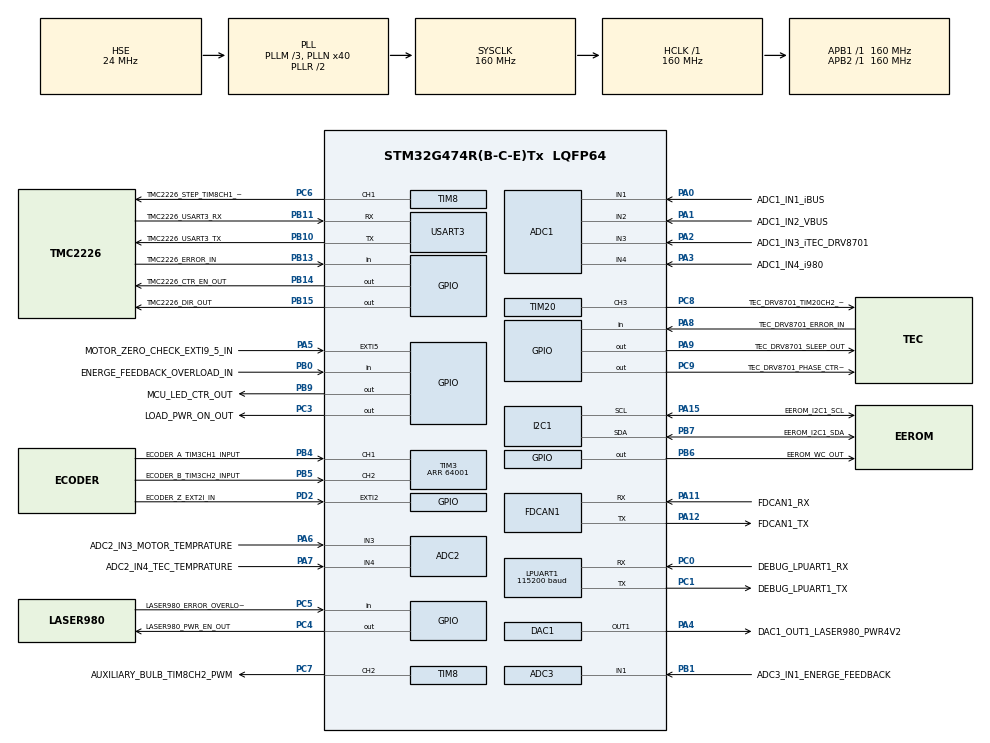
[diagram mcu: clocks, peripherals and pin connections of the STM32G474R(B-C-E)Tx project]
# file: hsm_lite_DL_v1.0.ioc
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ADC1.Channel-10\#ChannelRegularConversion=ADC_CHANNEL_3
ADC1.Channel-11\#ChannelRegularConversion=ADC_CHANNEL_4
ADC1.Channel-8\#ChannelRegularConversion=ADC_CHANNEL_1
ADC1.Channel-9\#ChannelRegularConversion=ADC_CHANNEL_2
ADC1.ContinuousConvMode=DISABLE
ADC1.DMAContinuousRequests=ENABLE
ADC1.DiscontinuousConvMode=DISABLE
ADC1.EOCSelection=ADC_EOC_SEQ_CONV
ADC1.EnableInjectedConversion=DISABLE
ADC1.EnableInjectedOversampling=DISABLE
ADC1.EnableRegularConversion=ENABLE
ADC1.ExternalTrigConv=ADC_EXTERNALTRIG_T1_TRGO2
ADC1.ExternalTrigConvEdge=ADC_EXTERNALTRIGCONVEDGE_FALLING
ADC1.LowPowerAutoWait=ENABLE
ADC1.Mode=ADC_MODE_INDEPENDENT
ADC1.NbrOfConversion=4
ADC1.NbrOfConversionFlag=1
ADC1.OffsetNumber-10\#ChannelRegularConversion=ADC_OFFSET_NONE
ADC1.OffsetNumber-11\#ChannelRegularConversion=ADC_OFFSET_NONE
ADC1.OffsetNumber-8\#ChannelRegularConversion=ADC_OFFSET_NONE
ADC1.OffsetNumber-9\#ChannelRegularConversion=ADC_OFFSET_NONE
ADC1.Rank-10\#ChannelRegularConversion=3
ADC1.Rank-11\#ChannelRegularConversion=4
ADC1.Rank-8\#ChannelRegularConversion=1
ADC1.Rank-9\#ChannelRegularConversion=2
ADC1.SamplingTime-10\#ChannelRegularConversion=ADC_SAMPLETIME_640CYCLES_5
ADC1.SamplingTime-11\#ChannelRegularConversion=ADC_SAMPLETIME_640CYCLES_5
ADC1.SamplingTime-8\#ChannelRegularConversion=ADC_SAMPLETIME_640CYCLES_5
ADC1.SamplingTime-9\#ChannelRegularConversion=ADC_SAMPLETIME_640CYCLES_5
ADC1.master=1
ADC2.Channel-0\#ChannelRegularConversion=ADC_CHANNEL_3
ADC2.Channel-1\#ChannelRegularConversion=ADC_CHANNEL_4
ADC2.ContinuousConvMode=DISABLE
ADC2.DMAContinuousRequests=ENABLE
ADC2.EOCSelection=ADC_EOC_SEQ_CONV
ADC2.ExternalTrigConv=ADC_EXTERNALTRIG_T1_TRGO
ADC2.ExternalTrigConvEdge=ADC_EXTERNALTRIGCONVEDGE_RISING
ADC2.LowPowerAutoWait=ENABLE
ADC2.NbrOfConversion=2
ADC2.NbrOfConversionFlag=1
ADC2.OffsetNumber-0\#ChannelRegularConversion=ADC_OFFSET_NONE
ADC2.OffsetNumber-1\#ChannelRegularConversion=ADC_OFFSET_NONE
ADC2.Rank-0\#ChannelRegularConversion=1
ADC2.Rank-1\#ChannelRegularConversion=2
ADC2.SamplingTime-0\#ChannelRegularConversion=ADC_SAMPLETIME_640CYCLES_5
ADC2.SamplingTime-1\#ChannelRegularConversion=ADC_SAMPLETIME_640CYCLES_5
ADC3.Channel-0\#ChannelRegularConversion=ADC_CHANNEL_1
ADC3.DMAContinuousRequests=ENABLE
ADC3.ExternalTrigConv=ADC_EXTERNALTRIG_T15_TRGO
ADC3.LowPowerAutoWait=ENABLE
ADC3.NbrOfConversionFlag=1
ADC3.OffsetNumber-0\#ChannelRegularConversion=ADC_OFFSET_NONE
ADC3.Rank-0\#ChannelRegularConversion=1
ADC3.SamplingTime-0\#ChannelRegularConversion=ADC_SAMPLETIME_247CYCLES_5
ADC3.master=1
DAC1.DAC_Trigger_OUT1-DAC_OUT1=DAC_TRIGGER_SOFTWARE
Dma.ADC1.0.Direction=DMA_PERIPH_TO_MEMORY
Dma.ADC1.0.EventEnable=DISABLE
Dma.ADC1.0.Instance=DMA1_Channel1
Dma.ADC1.0.MemDataAlignment=DMA_MDATAALIGN_HALFWORD
Dma.ADC1.0.MemInc=DMA_MINC_ENABLE
Dma.ADC1.0.Mode=DMA_CIRCULAR
Dma.ADC1.0.PeriphDataAlignment=DMA_PDATAALIGN_HALFWORD
Dma.ADC1.0.PeriphInc=DMA_PINC_DISABLE
Dma.ADC1.0.Polarity=HAL_DMAMUX_REQ_GEN_RISING
Dma.ADC1.0.Priority=DMA_PRIORITY_LOW
Dma.ADC1.0.RequestNumber=1
Dma.ADC1.0.SignalID=NONE
Dma.ADC1.0.SyncEnable=DISABLE
Dma.ADC1.0.SyncPolarity=HAL_DMAMUX_SYNC_NO_EVENT
Dma.ADC1.0.SyncRequestNumber=1
Dma.ADC1.0.SyncSignalID=NONE
Dma.ADC2.2.Direction=DMA_PERIPH_TO_MEMORY
Dma.ADC2.2.EventEnable=DISABLE
Dma.ADC2.2.Instance=DMA1_Channel2
Dma.ADC2.2.MemDataAlignment=DMA_MDATAALIGN_HALFWORD
Dma.ADC2.2.MemInc=DMA_MINC_ENABLE
Dma.ADC2.2.Mode=DMA_CIRCULAR
Dma.ADC2.2.PeriphDataAlignment=DMA_PDATAALIGN_HALFWORD
Dma.ADC2.2.PeriphInc=DMA_PINC_DISABLE
Dma.ADC2.2.Polarity=HAL_DMAMUX_REQ_GEN_RISING
Dma.ADC2.2.Priority=DMA_PRIORITY_LOW
Dma.ADC2.2.RequestNumber=1
Dma.ADC2.2.SignalID=NONE
Dma.ADC2.2.SyncEnable=DISABLE
Dma.ADC2.2.SyncPolarity=HAL_DMAMUX_SYNC_NO_EVENT
Dma.ADC2.2.SyncRequestNumber=1
Dma.ADC2.2.SyncSignalID=NONE
Dma.ADC3.1.Direction=DMA_PERIPH_TO_MEMORY
Dma.ADC3.1.EventEnable=DISABLE
Dma.ADC3.1.Instance=DMA2_Channel1
Dma.ADC3.1.MemDataAlignment=DMA_MDATAALIGN_HALFWORD
Dma.ADC3.1.MemInc=DMA_MINC_ENABLE
Dma.ADC3.1.Mode=DMA_CIRCULAR
Dma.ADC3.1.PeriphDataAlignment=DMA_PDATAALIGN_HALFWORD
Dma.ADC3.1.PeriphInc=DMA_PINC_DISABLE
Dma.ADC3.1.Polarity=HAL_DMAMUX_REQ_GEN_RISING
Dma.ADC3.1.Priority=DMA_PRIORITY_LOW
Dma.ADC3.1.RequestNumber=1
Dma.ADC3.1.SignalID=NONE
Dma.ADC3.1.SyncEnable=DISABLE
Dma.ADC3.1.SyncPolarity=HAL_DMAMUX_SYNC_NO_EVENT
Dma.ADC3.1.SyncRequestNumber=1
Dma.ADC3.1.SyncSignalID=NONE
Dma.Request0=ADC1
Dma.Request1=ADC3
Dma.Request2=ADC2
FDCAN1.AutoRetransmission=DISABLE
FDCAN1.CalculateBaudRateNominal=125000
FDCAN1.CalculateTimeBitNominal=8000
FDCAN1.CalculateTimeQuantumNominal=400.0
FDCAN1.ClockDivider=FDCAN_CLOCK_DIV1
FDCAN1.DataSyncJumpWidth=1
FDCAN1.DataTimeSeg1=8
FDCAN1.DataTimeSeg2=9
FDCAN1.Mode=FDCAN_MODE_NORMAL
FDCAN1.NominalPrescaler=64
FDCAN1.NominalSyncJumpWidth=1
FDCAN1.NominalTimeSeg1=10
FDCAN1.NominalTimeSeg2=9
FDCAN1.StdFiltersNbr=0
FDCAN1.TransmitPause=DISABLE
FREERTOS.BinarySemaphores01=prohotBinarySem02,Dynamic,NULL,Depleted;laserCloseBinarySem03,Dynamic,NULL,Depleted;poweroffBinarySem04,Dynamic,NULL,Depleted;secondHeartBinarySem04,Dynamic,NULL,Depleted
FREERTOS.Events01=motorEvent01,Dynamic,NULL;laserEvent02,Dynamic,NULL;deviceErrorEvent03,Dynamic,NULL;tecEvent04,Dynamic,NULL
FREERTOS.Queues01=motorPositonQueue01,4,uint32_t,0,Static,positonQueue01Buffer,positonQueue01ControlBlock
FREERTOS.Tasks01=defaultTask,26,256,StartDefaultTask,Default,NULL,Dynamic,NULL,NULL;myTask02,24,256,motorTask02,Default,NULL,Dynamic,NULL,NULL;myTask03,26,320,CANopenTask03,Default,NULL,Dynamic,NULL,NULL;myTask04,26,256,laserWorkTask04,Default,NULL,Dynamic,NULL,NULL;myTask05,27,256,laserProhotTask05,Default,NULL,Dynamic,NULL,NULL;myTask06,28,128,powerOffTask06,Default,NULL,Dynamic,NULL,NULL
FREERTOS.Timers01=laserWorkTimer01,laserWorkTimerCallback01,osTimerOnce,Default,NULL,Static,laserWorkTimer01ControlBlock;tecRunTimer02,tecRunCallback02,osTimerOnce,Default,NULL,Dynamic,NULL;secondsHeartTimer03,secondsHeartCallback03,osTimerPeriodic,Default,NULL,Dynamic,NULL
FREERTOS.configENABLE_FPU=1
FREERTOS.configTOTAL_HEAP_SIZE=32768
FREERTOS.configUSE_IDLE_HOOK=1
I2C1.Timing=0x30D29DE4
LPUART1.BaudRate=115200
LPUART1.FIFOMode=UART_FIFOMODE_DISABLE
LPUART1.Mode=UART_MODE_TX_RX
Mcu.Family=STM32G4
Mcu.Name=STM32G474R(B-C-E)Tx
Mcu.Package=LQFP64
NVIC.DMA1_Channel1_IRQn=true\:5\:0\:false\:false\:true\:true\:false\:true\:true
NVIC.DMA1_Channel2_IRQn=true\:5\:0\:false\:false\:true\:true\:false\:true\:true
NVIC.DMA2_Channel1_IRQn=true\:5\:0\:false\:false\:true\:false\:false\:true\:true
NVIC.EXTI2_IRQn=true\:5\:0\:false\:false\:true\:true\:true\:true\:true
NVIC.PriorityGroup=NVIC_PRIORITYGROUP_4
NVIC.TIM3_IRQn=true\:5\:0\:false\:false\:true\:true\:true\:true\:true
NVIC.TIM4_IRQn=true\:5\:0\:false\:false\:true\:true\:true\:true\:true
NVIC.TIM6_DAC_IRQn=true\:15\:0\:false\:false\:true\:false\:false\:true\:true
NVIC.TimeBase=TIM6_DAC_IRQn
NVIC.TimeBaseIP=TIM6
PA0.GPIO_Label=ADC1_IN1_iBUS
PA0.Mode=IN1-Single-Ended
PA0.Signal=ADC1_IN1
PA1.GPIO_Label=ADC1_IN2_VBUS
PA1.Mode=IN2-Single-Ended
PA1.Signal=ADC1_IN2
PA11.GPIO_Label=FDCAN1_RX
PA11.GPIO_PuPd=GPIO_NOPULL
PA11.Mode=FDCAN_Activate
PA11.Signal=FDCAN1_RX
PA12.GPIO_Label=FDCAN1_TX
PA12.GPIO_PuPd=GPIO_NOPULL
PA12.GPIO_Speed=GPIO_SPEED_FREQ_MEDIUM
PA12.Mode=FDCAN_Activate
PA12.Signal=FDCAN1_TX
PA13.Mode=Serial_Wire
PA13.Signal=SYS_JTMS-SWDIO
PA14.Mode=Serial_Wire
PA14.Signal=SYS_JTCK-SWCLK
PA15.GPIO_Label=EEROM_I2C1_SCL
PA15.Mode=I2C
PA15.Signal=I2C1_SCL
PA2.GPIO_Label=ADC1_IN3_iTEC_DRV8701
PA2.Mode=IN3-Single-Ended
PA2.Signal=ADC1_IN3
PA3.GPIO_Label=ADC1_IN4_i980
PA3.Mode=IN4-Single-Ended
PA3.Signal=ADC1_IN4
PA4.GPIO_Label=DAC1_OUT1_LASER980_PWR4V2
PA4.Signal=COMP_DAC11_group
PA5.GPIO_Label=MOTOR_ZERO_CHECK_EXTI9_5_IN
PA5.GPIO_ModeDefaultEXTI=GPIO_MODE_IT_RISING
PA5.Signal=GPXTI5
PA6.GPIO_Label=ADC2_IN3_MOTOR_TEMPRATURE
PA6.Mode=IN3-Single-Ended
PA6.Signal=ADC2_IN3
PA7.GPIO_Label=ADC2_IN4_TEC_TEMPRATURE
PA7.Mode=IN4-Single-Ended
PA7.Signal=ADC2_IN4
PA8.GPIO_Label=TEC_DRV8701_ERROR_IN
PA8.Signal=GPIO_Input
PA9.GPIO_Label=TEC_DRV8701_SLEEP_OUT
PA9.GPIO_ModeDefaultOutputPP=GPIO_MODE_OUTPUT_PP
PA9.GPIO_PuPd=GPIO_NOPULL
PA9.Signal=GPIO_Output
PB0.GPIO_Label=ENERGE_FEEDBACK_OVERLOAD_IN
PB0.Signal=GPIO_Input
PB1.GPIO_Label=ADC3_IN1_ENERGE_FEEDBACK
PB1.Mode=IN1-Single-Ended
PB1.Signal=ADC3_IN1
PB10.GPIO_Label=TMC2226_USART3_TX
PB10.Mode=Asynchronous
PB10.Signal=USART3_TX
PB11.GPIO_Label=TMC2226_USART3_RX
PB11.Mode=Asynchronous
PB11.Signal=USART3_RX
PB13.GPIO_Label=TMC2226_ERROR_IN
PB13.Signal=GPIO_Input
PB14.GPIO_Label=TMC2226_CTR_EN_OUT
PB14.Signal=GPIO_Output
PB15.GPIO_Label=TMC2226_DIR_OUT
PB15.Signal=GPIO_Output
PB4.GPIO_Label=ECODER_A_TIM3CH1_INPUT
PB4.Signal=S_TIM3_CH1
PB5.GPIO_Label=ECODER_B_TIM3CH2_INPUT
PB5.Signal=S_TIM3_CH2
PB6.GPIO_Label=EEROM_WC_OUT
PB6.Signal=GPIO_Output
PB7.GPIO_Label=EEROM_I2C1_SDA
PB7.Mode=I2C
PB7.Signal=I2C1_SDA
PB9.GPIO_Label=MCU_LED_CTR_OUT
PB9.Signal=GPIO_Output
PC0.GPIO_Label=DEBUG_LPUART1_RX
PC0.Mode=Asynchronous
PC0.Signal=LPUART1_RX
PC1.GPIO_Label=DEBUG_LPUART1_TX
PC1.Mode=Asynchronous
PC1.Signal=LPUART1_TX
PC3.GPIO_Label=LOAD_PWR_ON_OUT
PC3.Signal=GPIO_Output
PC4.GPIO_Label=LASER980_PWR_EN_OUT
PC4.Signal=GPIO_Output
PC5.GPIO_Label=LASER980_ERROR_OVERLOAD_IN
PC5.Signal=GPIO_Input
PC6.GPIO_Label=TMC2226_STEP_TIM8CH1_PWM
PC6.Signal=S_TIM8_CH1
PC7.GPIO_Label=AUXILIARY_BULB_TIM8CH2_PWM
PC7.Signal=S_TIM8_CH2
PC8.GPIO_Label=TEC_DRV8701_TIM20CH2_PWM
PC8.Signal=S_TIM20_CH3
PC9.GPIO_Label=TEC_DRV8701_PHASE_CTR_OUT
PC9.Signal=GPIO_Output
PD2.GPIO_Label=ECODER_Z_EXT2I_IN
PD2.GPIO_ModeDefaultEXTI=GPIO_MODE_IT_FALLING
PD2.Signal=GPXTI2
PF0-OSC_IN.Mode=HSE-External-Oscillator
PF0-OSC_IN.Signal=RCC_OSC_IN
PF1-OSC_OUT.Mode=HSE-External-Oscillator
PF1-OSC_OUT.Signal=RCC_OSC_OUT
ProjectManager.HeapSize=0x2000
ProjectManager.StackSize=0x400
ProjectManager.TargetToolchain=MDK-ARM V5.32
RCC.ADC12Freq_Value=160000000
RCC.ADC345Freq_Value=160000000
RCC.AHBFreq_Value=160000000
RCC.APB1Freq_Value=160000000
RCC.APB1TimFreq_Value=160000000
RCC.APB2Freq_Value=160000000
RCC.APB2TimFreq_Value=160000000
RCC.CortexFreq_Value=160000000
RCC.EXTERNAL_CLOCK_VALUE=12288000
RCC.HCLKFreq_Value=160000000
RCC.HSE_VALUE=24000000
RCC.HSI48_VALUE=48000000
RCC.HSI_VALUE=16000000
RCC.LSE_VALUE=32768
RCC.PLLM=RCC_PLLM_DIV3
RCC.PLLN=40
RCC.PLLSourceVirtual=RCC_PLLSOURCE_HSE
RCC.SYSCLKFreq_VALUE=160000000
RCC.SYSCLKSource=RCC_SYSCLKSOURCE_PLLCLK
RCC.USBFreq_Value=160000000
RCC.VCOOutputFreq_Value=320000000
SH.COMP_DAC11_group.0=DAC1_OUT1,DAC_OUT1
SH.S_TIM20_CH3.0=TIM20_CH3,PWM Generation3 CH3
SH.S_TIM3_CH1.0=TIM3_CH1,Encoder_Interface
SH.S_TIM3_CH2.0=TIM3_CH2,Encoder_Interface
SH.S_TIM8_CH1.0=TIM8_CH1,PWM Generation1 CH1
SH.S_TIM8_CH2.0=TIM8_CH2,PWM Generation2 CH2
TIM1.AutoReloadPreload=TIM_AUTORELOAD_PRELOAD_ENABLE
TIM1.Channel-Output\ Compare1\ No\ Output=TIM_CHANNEL_1
TIM1.PeriodNoDither=3999
TIM1.Prescaler=1599
TIM1.PulseNoDither_1=1999
TIM1.TIM_MasterOutputTrigger=TIM_TRGO_UPDATE
TIM1.TIM_MasterOutputTrigger2=TIM_TRGO2_OC1
TIM1.TIM_MasterSlaveMode=TIM_MASTERSLAVEMODE_ENABLE
TIM15.AutoReloadPreload=TIM_AUTORELOAD_PRELOAD_ENABLE
TIM15.PeriodNoDither=1999
TIM15.Prescaler=1599
TIM15.TIM_MasterOutputTrigger=TIM_TRGO_UPDATE
TIM15.TIM_MasterSlaveMode=TIM_MASTERSLAVEMODE_ENABLE
TIM20.AutoReloadPreload=TIM_AUTORELOAD_PRELOAD_ENABLE
TIM20.Channel-PWM\ Generation3\ CH3=TIM_CHANNEL_3
TIM20.PeriodNoDither=100
TIM20.Prescaler=15
TIM20.TIM_MasterOutputTrigger=TIM_TRGO_RESET
TIM20.TIM_MasterSlaveMode=TIM_MASTERSLAVEMODE_ENABLE
TIM3.AutoReloadPreload=TIM_AUTORELOAD_PRELOAD_ENABLE
TIM3.Channel-Output\ Compare3\ No\ Output=TIM_CHANNEL_3
TIM3.EncoderMode=TIM_ENCODERMODE_X1_TI1
TIM3.OC3Preload=DISABLE
TIM3.PeriodNoDither=64001
TIM3.TIM_MasterOutputTrigger=TIM_TRGO_OC3REF
TIM3.TIM_MasterSlaveMode=TIM_MASTERSLAVEMODE_ENABLE
TIM4.AutoReloadPreload=TIM_AUTORELOAD_PRELOAD_DISABLE
TIM4.Dithering=Disable
TIM4.PeriodNoDither=3500
TIM4.Prescaler=15
TIM4.TIM_MasterOutputTrigger=TIM_TRGO_UPDATE
TIM4.TIM_MasterSlaveMode=TIM_MASTERSLAVEMODE_DISABLE
TIM8.AutoReloadPreload=TIM_AUTORELOAD_PRELOAD_ENABLE
TIM8.Channel-PWM\ Generation1\ CH1=TIM_CHANNEL_1
TIM8.Channel-PWM\ Generation2\ CH2=TIM_CHANNEL_2
TIM8.CounterMode=TIM_COUNTERMODE_UP
TIM8.OCMode_PWM-PWM\ Generation2\ CH2=TIM_OCMODE_PWM1
TIM8.PeriodNoDither=500
TIM8.Prescaler=159
TIM8.PulseNoDither_1=200
TIM8.PulseNoDither_2=100
TIM8.TIM_MasterOutputTrigger=TIM_TRGO_UPDATE
TIM8.TIM_MasterOutputTrigger2=TIM_TRGO2_OC4REF_RISINGFALLING
TIM8.TIM_MasterSlaveMode=TIM_MASTERSLAVEMODE_ENABLE
USART3.VirtualMode-Asynchronous=VM_ASYNC
VP_FREERTOS_VS_CMSIS_V2.Mode=CMSIS_V2
VP_IWDG_VS_IWDG.Mode=IWDG_Activate
VP_SYS_VS_DBSignals.Mode=DisableDeadBatterySignals
VP_SYS_VS_tim6.Mode=TIM6
VP_TIM15_VS_ClockSourceINT.Mode=Internal
VP_TIM1_VS_no_output1.Mode=Output Compare1 No Output
VP_TIM3_VS_no_output3.Mode=Output Compare3 No Output
VP_TIM4_VS_ClockSourceITR.Mode=TriggerSource_ITR5
VP_TIM4_VS_ControllerModeClock.Mode=Clock Mode
board=custom

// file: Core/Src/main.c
/* USER CODE BEGIN Header */
/**
  ******************************************************************************
  * @file           : main.c
  * @brief          : Main program body
  ******************************************************************************
  * @attention
  *
  * Copyright (c) 2025 STMicroelectronics.
  * All rights reserved.
  *
  * This software is licensed under terms that can be found in the LICENSE file
  * in the root directory of this software component.
  * If no LICENSE file comes with this software, it is provided AS-IS.
  *
  ******************************************************************************
  */
/* USER CODE END Header */
#include "main.h"
#include "cmsis_os.h"
#include "adc.h"
#include "dac.h"
#include "dma.h"
#include "fdcan.h"
#include "i2c.h"
#include "iwdg.h"
#include "usart.h"
#include "tim.h"
#include "gpio.h"

/* USER CODE BEGIN Includes */
#include "common_function.h"
#include "string.h"
/* USER CODE END Includes */

void SystemClock_Config(void);
void MX_FREERTOS_Init(void);

int main(void)
{

  /* MCU Configuration--------------------------------------------------------*/

  /* Reset of all peripherals, Initializes the Flash interface and the Systick. */
  HAL_Init();

  /* Configure the system clock */
  SystemClock_Config();

  /* Initialize all configured peripherals */
  MX_GPIO_Init();
  MX_DMA_Init();
  MX_ADC1_Init();
  MX_ADC2_Init();
  MX_ADC3_Init();
  MX_DAC1_Init();
  MX_FDCAN1_Init();
  MX_I2C1_Init();
  MX_LPUART1_UART_Init();
  MX_TIM3_Init();
  MX_TIM8_Init();
  MX_TIM20_Init();
  MX_USART3_UART_Init();
  MX_TIM4_Init();
  MX_IWDG_Init();
  MX_TIM1_Init();
  MX_TIM15_Init();
  /* USER CODE BEGIN 2 */
  DWT_Init();
  char verBuff[19]={0};
  memcpy(verBuff,__TIME__,8);
  memcpy(&verBuff[8],__DATE__,11);
  if(verBuff[12]<'1') verBuff[12]='0';
  #ifdef DEBUG_MSG_UART
  DEBUG_PRINTF("hsm_dl_V0.0.%c%c%c%c%c%c%c%c%c%c%c%c --DATE=%s\r\n",verBuff[0],verBuff[1],verBuff[3],verBuff[4],verBuff[6],verBuff[7],verBuff[12],verBuff[13],verBuff[15],verBuff[16],verBuff[17],verBuff[18],__DATE__);
  #else
  printf("hsm_dl_V0.0.%c%c%c%c%c%c%c%c%c%c%c%c --DATE=%s\r\n",verBuff[0],verBuff[1],verBuff[3],verBuff[4],verBuff[6],verBuff[7],verBuff[12],verBuff[13],verBuff[15],verBuff[16],verBuff[17],verBuff[18],__DATE__);
  #endif
  /* USER CODE END 2 */

  /* Init scheduler */
  osKernelInitialize();

  /* Call init function for freertos objects (in cmsis_os2.c) */
  MX_FREERTOS_Init();

  /* Start scheduler */
  osKernelStart();

  /* We should never get here as control is now taken by the scheduler */

  /* Infinite loop */
  while (1)
  {

  }
}

void SystemClock_Config(void)
{
  RCC_OscInitTypeDef RCC_OscInitStruct = {0};
  RCC_ClkInitTypeDef RCC_ClkInitStruct = {0};

  /** Configure the main internal regulator output voltage
  */
  HAL_PWREx_ControlVoltageScaling(PWR_REGULATOR_VOLTAGE_SCALE1_BOOST);

  /** Initializes the RCC Oscillators according to the specified parameters
  * in the RCC_OscInitTypeDef structure.
  */
  RCC_OscInitStruct.OscillatorType = RCC_OSCILLATORTYPE_LSI|RCC_OSCILLATORTYPE_HSE;
  RCC_OscInitStruct.HSEState = RCC_HSE_ON;
  RCC_OscInitStruct.LSIState = RCC_LSI_ON;
  RCC_OscInitStruct.PLL.PLLState = RCC_PLL_ON;
  RCC_OscInitStruct.PLL.PLLSource = RCC_PLLSOURCE_HSE;
  RCC_OscInitStruct.PLL.PLLM = RCC_PLLM_DIV3;
  RCC_OscInitStruct.PLL.PLLN = 40;
  RCC_OscInitStruct.PLL.PLLP = RCC_PLLP_DIV2;
  RCC_OscInitStruct.PLL.PLLQ = RCC_PLLQ_DIV2;
  RCC_OscInitStruct.PLL.PLLR = RCC_PLLR_DIV2;
  if (HAL_RCC_OscConfig(&RCC_OscInitStruct) != HAL_OK)
  {
    Error_Handler();
  }

  /** Initializes the CPU, AHB and APB buses clocks
  */
  RCC_ClkInitStruct.ClockType = RCC_CLOCKTYPE_HCLK|RCC_CLOCKTYPE_SYSCLK
                              |RCC_CLOCKTYPE_PCLK1|RCC_CLOCKTYPE_PCLK2;
  RCC_ClkInitStruct.SYSCLKSource = RCC_SYSCLKSOURCE_PLLCLK;
  RCC_ClkInitStruct.AHBCLKDivider = RCC_SYSCLK_DIV1;
  RCC_ClkInitStruct.APB1CLKDivider = RCC_HCLK_DIV1;
  RCC_ClkInitStruct.APB2CLKDivider = RCC_HCLK_DIV1;

  if (HAL_RCC_ClockConfig(&RCC_ClkInitStruct, FLASH_LATENCY_4) != HAL_OK)
  {
    Error_Handler();
  }
}

/* USER CODE BEGIN 4 */
#include "tmc2226_step_bsp.h"
/* USER CODE END 4 */

void HAL_TIM_PeriodElapsedCallback(TIM_HandleTypeDef *htim)
{
  if (htim->Instance == TIM6) {
    HAL_IncTick();
  }
  /* USER CODE BEGIN Callback 1 */
  if (htim->Instance == TIM4) {
    app_motor_stop_fresh_status();
    HAL_TIM_Base_Stop_IT(&htim4);
    DEBUG_PRINTF("steps overflow\r\n ");
  }
  /* USER CODE END Callback 1 */
}

void Error_Handler(void)
{
  __disable_irq();
  while (1)
  {
  }
}

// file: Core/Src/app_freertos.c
/* USER CODE BEGIN Header */
/**
  ******************************************************************************
  * File Name          : app_freertos.c
  * Description        : Code for freertos applications
  ******************************************************************************
  * @attention
  *
  * Copyright (c) 2025 STMicroelectronics.
  * All rights reserved.
  *
  * This software is licensed under terms that can be found in the LICENSE file
  * in the root directory of this software component.
  * If no LICENSE file comes with this software, it is provided AS-IS.
  *
  ******************************************************************************
  */
/* USER CODE END Header */

#include "FreeRTOS.h"
#include "task.h"
#include "main.h"
#include "cmsis_os.h"

/* USER CODE BEGIN Includes */
#include "string.h"
#include "stdio.h"
#include "adc.h"
#include "tim.h"
#include "dac.h"
#include "gpio.h"
#include "fdcan.h"
#include "tmc2226_step_bsp.h"
#include "eeprom_bsp.h"
#include "tec_control_bsp.h"
#include "CAN_modbusRTU_bsp.h"
#include "common_function.h"
/* USER CODE END Includes */

typedef StaticQueue_t osStaticMessageQDef_t;
typedef StaticTimer_t osStaticTimerDef_t;

/* USER CODE BEGIN PD */
//motorEvent01Handle
#define EVENTS_MOTOR_ZERO_BIT0  			    0x01//0校准
#define EVENTS_MOTOR_IDLE_BIT1  					0x01<<1 //电机空闲
#define EVENTS_MOTOR_TEMPRATURE_BIT2 					0x01<<2 //电机温度正常
#define EVENTS_MOTOR_OK_ALL_BITS_MASK        	(EVENTS_MOTOR_ZERO_BIT0|EVENTS_MOTOR_IDLE_BIT1)
//laserEvent02Handle
#define EVENTS_LASER_POSITON_BIT0 			 0x01
#define EVENTS_LASER_TEMPRATUR_BIT1  		 0x01<<1
#define EVENTS_LASER_VOLTAGE_BIT2  			 0x01<<2
#define EVENTS_LASER_OK_ALL_BITS_MASK      (EVENTS_LASER_POSITON_BIT0|EVENTS_LASER_TEMPRATUR_BIT1|EVENTS_LASER_VOLTAGE_BIT2)

//deviceErrorEvent03
#define EVENTS_DEV_ERR_CAN_HEART_BIT0 			       0x01
#define EVENTS_DEV_ERR_TEC_CTR_BIT1  		           0x01<<1
#define EVENTS_DEV_ERR_MOTOR_TMC_BIT2  		         0x01<<2
#define EVENTS_DEV_ERR_LASER_TEMPRATURE_BIT3  		 0x01<<3
#define EVENTS_DEV_ERR_MOTOR_TEMPRATURE_BIT4 		   0x01<<4
#define EVENTS_DEV_ERR_POSITON_BIT5 			         0x01<<5
#define EVENTS_DEV_ERR_VBUS_BIT6 			             0x01<<6
#define EVENTS_DEV_ERR_IBUS_BIT7			             0x01<<7
#define EVENTS_DEV_ERR_ALL_BITS_MASK  (EVENTS_DEV_ERR_CAN_HEART_BIT0|EVENTS_DEV_ERR_TEC_CTR_BIT1|EVENTS_DEV_ERR_MOTOR_TMC_BIT2\
                                      |EVENTS_DEV_ERR_LASER_TEMPRATURE_BIT3|EVENTS_DEV_ERR_MOTOR_TEMPRATURE_BIT4 \
                                      |EVENTS_DEV_ERR_POSITON_BIT5|EVENTS_DEV_ERR_VBUS_BIT6|EVENTS_DEV_ERR_IBUS_BIT7)

//tecEvent04Handle
#define EVENTS_TEC_STA_IDLE_BIT0 			 0x01 //1空闲，0运行
#define EVENTS_TEC_ERR_BIT1 			 0x01<<1//1无故障
#define EVENTS_TEC_OK_ALL_BITS_MASK  (EVENTS_TEC_STA_IDLE_BIT0|EVENTS_TEC_ERR_BIT1)
/* USER CODE END PD */

/* USER CODE BEGIN PM */
HSM_DL_STATUS hsm_dl_sta;
U_SYS_CONFIG_PARAM u_sys_param;
U_SYS_CONFIG_PARAM u_sys_default_param;
LASER_CTR_PARAM  laser_ctr_param;
/* USER CODE END PM */

/* Definitions for defaultTask */
osThreadId_t defaultTaskHandle;
const osThreadAttr_t defaultTask_attributes = {
  .name = "defaultTask",
  .priority = (osPriority_t) osPriorityNormal2,
  .stack_size = 256 * 4
};
/* Definitions for myTask02 */
osThreadId_t myTask02Handle;
const osThreadAttr_t myTask02_attributes = {
  .name = "myTask02",
  .priority = (osPriority_t) osPriorityNormal,
  .stack_size = 256 * 4
};
/* Definitions for myTask03 */
osThreadId_t myTask03Handle;
const osThreadAttr_t myTask03_attributes = {
  .name = "myTask03",
  .priority = (osPriority_t) osPriorityNormal2,
  .stack_size = 320 * 4
};
/* Definitions for myTask04 */
osThreadId_t myTask04Handle;
const osThreadAttr_t myTask04_attributes = {
  .name = "myTask04",
  .priority = (osPriority_t) osPriorityNormal2,
  .stack_size = 256 * 4
};
/* Definitions for myTask05 */
osThreadId_t myTask05Handle;
const osThreadAttr_t myTask05_attributes = {
  .name = "myTask05",
  .priority = (osPriority_t) osPriorityNormal3,
  .stack_size = 256 * 4
};
/* Definitions for myTask06 */
osThreadId_t myTask06Handle;
const osThreadAttr_t myTask06_attributes = {
  .name = "myTask06",
  .priority = (osPriority_t) osPriorityNormal4,
  .stack_size = 128 * 4
};
/* Definitions for motorPositonQueue01 */
osMessageQueueId_t motorPositonQueue01Handle;
uint8_t positonQueue01Buffer[ 3 * sizeof( uint32_t ) ];
osStaticMessageQDef_t positonQueue01ControlBlock;
const osMessageQueueAttr_t motorPositonQueue01_attributes = {
  .name = "motorPositonQueue01",
  .cb_mem = &positonQueue01ControlBlock,
  .cb_size = sizeof(positonQueue01ControlBlock),
  .mq_mem = &positonQueue01Buffer,
  .mq_size = sizeof(positonQueue01Buffer)
};
/* Definitions for laserWorkTimer01 */
osTimerId_t laserWorkTimer01Handle;
osStaticTimerDef_t laserWorkTimer01ControlBlock;
const osTimerAttr_t laserWorkTimer01_attributes = {
  .name = "laserWorkTimer01",
  .cb_mem = &laserWorkTimer01ControlBlock,
  .cb_size = sizeof(laserWorkTimer01ControlBlock),
};
/* Definitions for tecRunTimer02 */
osTimerId_t tecRunTimer02Handle;
const osTimerAttr_t tecRunTimer02_attributes = {
  .name = "tecRunTimer02"
};
/* Definitions for secondsHeartTimer03 */
osTimerId_t secondsHeartTimer03Handle;
const osTimerAttr_t secondsHeartTimer03_attributes = {
  .name = "secondsHeartTimer03"
};
/* Definitions for prohotBinarySem02 */
osSemaphoreId_t prohotBinarySem02Handle;
const osSemaphoreAttr_t prohotBinarySem02_attributes = {
  .name = "prohotBinarySem02"
};
/* Definitions for laserCloseBinarySem03 */
osSemaphoreId_t laserCloseBinarySem03Handle;
const osSemaphoreAttr_t laserCloseBinarySem03_attributes = {
  .name = "laserCloseBinarySem03"
};
/* Definitions for poweroffBinarySem04 */
osSemaphoreId_t poweroffBinarySem04Handle;
const osSemaphoreAttr_t poweroffBinarySem04_attributes = {
  .name = "poweroffBinarySem04"
};
/* Definitions for secondHeartBinarySem04 */
osSemaphoreId_t secondHeartBinarySem04Handle;
const osSemaphoreAttr_t secondHeartBinarySem04_attributes = {
  .name = "secondHeartBinarySem04"
};
/* Definitions for motorEvent01 */
osEventFlagsId_t motorEvent01Handle;
const osEventFlagsAttr_t motorEvent01_attributes = {
  .name = "motorEvent01"
};
/* Definitions for laserEvent02 */
osEventFlagsId_t laserEvent02Handle;
const osEventFlagsAttr_t laserEvent02_attributes = {
  .name = "laserEvent02"
};
/* Definitions for deviceErrorEvent03 */
osEventFlagsId_t deviceErrorEvent03Handle;
const osEventFlagsAttr_t deviceErrorEvent03_attributes = {
  .name = "deviceErrorEvent03"
};
/* Definitions for tecEvent04 */
osEventFlagsId_t tecEvent04Handle;
const osEventFlagsAttr_t tecEvent04_attributes = {
  .name = "tecEvent04"
};

/* USER CODE BEGIN FunctionPrototypes */
void app_tec_ctr_semo(void);
void app_tec_auto_manage(void);
unsigned short int  app_laser_980_energe_to_voltage(unsigned short int energe);
void app_motor_err_handle(osStatus_t errSta);
void app_laser_prohot_semo(void);
void app_sys_param_load(void);
unsigned char app_sys_param_save_data(void);
/* USER CODE END FunctionPrototypes */

void StartDefaultTask(void *argument);
void motorTask02(void *argument);
void CANopenTask03(void *argument);
void laserWorkTask04(void *argument);
void laserProhotTask05(void *argument);
void powerOffTask06(void *argument);
void laserWorkTimerCallback01(void *argument);
void tecRunCallback02(void *argument);
void secondsHeartCallback03(void *argument);

void MX_FREERTOS_Init(void); /* (MISRA C 2004 rule 8.1) */

/* Hook prototypes */
void vApplicationIdleHook(void);

/* USER CODE BEGIN 2 */
void vApplicationIdleHook( void )
{
   /* vApplicationIdleHook() will only be called if configUSE_IDLE_HOOK is set
   to 1 in FreeRTOSConfig.h. It will be called on each iteration of the idle
   task. It is essential that code added to this hook function never attempts
   to block in any way (for example, call xQueueReceive() with a block time
   specified, or call vTaskDelay()). If the application makes use of the
   vTaskDelete() API function (as this demo application does) then it is also
   important that vApplicationIdleHook() is permitted to return to its calling
   function, because it is the responsibility of the idle task to clean up
   memory allocated by the kernel to any task that has since been deleted. */

   #ifdef IWDG_USED
   HAL_IWDG_Refresh(&hiwdg);
   #endif
}
/* USER CODE END 2 */

void MX_FREERTOS_Init(void) {

  /* Create the semaphores(s) */
  /* creation of prohotBinarySem02 */
  prohotBinarySem02Handle = osSemaphoreNew(1, 0, &prohotBinarySem02_attributes);

  /* creation of laserCloseBinarySem03 */
  laserCloseBinarySem03Handle = osSemaphoreNew(1, 0, &laserCloseBinarySem03_attributes);

  /* creation of poweroffBinarySem04 */
  poweroffBinarySem04Handle = osSemaphoreNew(1, 0, &poweroffBinarySem04_attributes);

  /* creation of secondHeartBinarySem04 */
  secondHeartBinarySem04Handle = osSemaphoreNew(1, 1, &secondHeartBinarySem04_attributes);

  /* Create the timer(s) */
  /* creation of laserWorkTimer01 */
  laserWorkTimer01Handle = osTimerNew(laserWorkTimerCallback01, osTimerOnce, NULL, &laserWorkTimer01_attributes);

  /* creation of tecRunTimer02 */
  tecRunTimer02Handle = osTimerNew(tecRunCallback02, osTimerOnce, NULL, &tecRunTimer02_attributes);

  /* creation of secondsHeartTimer03 */
  secondsHeartTimer03Handle = osTimerNew(secondsHeartCallback03, osTimerPeriodic, NULL, &secondsHeartTimer03_attributes);

  /* Create the queue(s) */
  /* creation of motorPositonQueue01 */
  motorPositonQueue01Handle = osMessageQueueNew (3, sizeof(uint32_t), &motorPositonQueue01_attributes);

  /* Create the thread(s) */
  /* creation of defaultTask */
  defaultTaskHandle = osThreadNew(StartDefaultTask, NULL, &defaultTask_attributes);

  /* creation of myTask02 */
  myTask02Handle = osThreadNew(motorTask02, NULL, &myTask02_attributes);

  /* creation of myTask03 */
  myTask03Handle = osThreadNew(CANopenTask03, NULL, &myTask03_attributes);

  /* creation of myTask04 */
  myTask04Handle = osThreadNew(laserWorkTask04, NULL, &myTask04_attributes);

  /* creation of myTask05 */
  myTask05Handle = osThreadNew(laserProhotTask05, NULL, &myTask05_attributes);

  /* creation of myTask06 */
  myTask06Handle = osThreadNew(powerOffTask06, NULL, &myTask06_attributes);

  /* Create the event(s) */
  /* creation of motorEvent01 */
  motorEvent01Handle = osEventFlagsNew(&motorEvent01_attributes);

  /* creation of laserEvent02 */
  laserEvent02Handle = osEventFlagsNew(&laserEvent02_attributes);

  /* creation of deviceErrorEvent03 */
  deviceErrorEvent03Handle = osEventFlagsNew(&deviceErrorEvent03_attributes);

  /* creation of tecEvent04 */
  tecEvent04Handle = osEventFlagsNew(&tecEvent04_attributes);

}

void StartDefaultTask(void *argument)
{
  /* USER CODE BEGIN StartDefaultTask */
  /* Infinite loop */
  app_load_power_switch( ENABLE);
  app_start_multi_channel_adc();
  tec_init( );
  tec_stop();
  EEPROM_M24C32_init();
  app_sys_param_load();
  float local_disp;
   unsigned char lowVoltageFlag;
  osDelay(1000);
	osTimerStart(secondsHeartTimer03Handle,SYS_1_SECOND_TICKS);
  for(;;)
  {
    app_get_adc_value(AD1_CH1_IBUS,&hsm_dl_sta.real_ibus);
   // DEBUG_PRINTF("AD:iBus=%.1fmA",hsm_dl_sta.real_ibus);
    app_get_adc_value(AD1_CH2_VBUS,&hsm_dl_sta.real_Vbus);
    if(hsm_dl_sta.real_Vbus<12.00&&lowVoltageFlag==0)
    {
      lowVoltageFlag=1;
     // DEBUG_PRINTF(" low voltage,power off !");
      osSemaphoreRelease(poweroffBinarySem04Handle);
    }
    else
    {
      if(hsm_dl_sta.real_Vbus>14.00) lowVoltageFlag=0;
    }
    //DEBUG_PRINTF(" vBus=%.2fV",hsm_dl_sta.real_Vbus);
    app_get_adc_value(AD1_CH3_I_TEC,&local_disp);
    //(" i_TEC=%.1f",local_disp);
    app_get_adc_value(AD2_CH3_NTC_MOTOR_TEMPRATURE,&local_disp);
    hsm_dl_sta.real_tmc_temprature=local_disp;
    if(hsm_dl_sta.real_tmc_temprature>MOTOR_TMC_PROTECT_TEMPRATUR)
    {//high
      unsigned int motor_events=osEventFlagsGet(motorEvent01Handle);
      if((motor_events&EVENTS_MOTOR_IDLE_BIT1)!=EVENTS_MOTOR_IDLE_BIT1 ) app_motor_err_handle(osError);
      osEventFlagsClear(motorEvent01Handle, EVENTS_MOTOR_TEMPRATURE_BIT2);
    }
    else osEventFlagsSet(motorEvent01Handle, EVENTS_MOTOR_TEMPRATURE_BIT2);
   // DEBUG_PRINTF(" motor_T=%.2f℃",hsm_dl_sta.real_tmc_temprature);
    app_get_adc_value(AD2_CH4_TEC_TEMPRATURE,&local_disp);
    u_s_l980.sta.realtemprature=(short int )(local_disp*10);
    u_sys_param.sys_config_param.targetTempratureSet=240;
   // DEBUG_PRINTF(" laser_tec_T=%.1f℃ target=%d",u_s_l980.sta.realtemprature*0.1,u_sys_param.sys_config_param.targetTempratureSet);
    app_get_adc_value(AD3_CH1_ENERGE_FEEDBACK,&local_disp);
    u_s_l980.sta.energeFeedback=(unsigned short int)local_disp;
    if(osSemaphoreAcquire(secondHeartBinarySem04Handle,L980_CAN_MINI_TIME_MS)==osOK)
    {
     // DEBUG_PRINTF(" energe=%dmV\r\n",u_s_l980.sta.energeFeedback);
      //DEBUG_PRINTF("POSITON:pos=%dμm\r\n",u_s_l980.sta.realPosition);
      HAL_GPIO_TogglePin(MCU_LED_CTR_OUT_GPIO_Port,MCU_LED_CTR_OUT_Pin);
      app_tec_auto_manage();
    }
    osDelay(L980_CAN_MINI_TIME_MS);
  }
  /* USER CODE END StartDefaultTask */
}

void motorTask02(void *argument)
{
  /* USER CODE BEGIN motorTask02 */
  /* Infinite loop */
  tmc2226_init();
  unsigned int m_timeOut=0;
  osDelay(1000);
  osStatus_t u_m_sta;
  U_MOTOR_CTR_MESSAGE u_ctr_rx_msg;
  unsigned int motor_events;
  for(;;)
  {
    motor_events = osEventFlagsGet(motorEvent01Handle);
    u_s_l980.sta.realPosition=app_get_motor_real_position();
    if((motor_events&EVENTS_MOTOR_ZERO_BIT0)==EVENTS_MOTOR_ZERO_BIT0 )
    {
      if((motor_events&EVENTS_MOTOR_IDLE_BIT1)==EVENTS_MOTOR_IDLE_BIT1)
      {//idle
        u_m_sta = osMessageQueueGet(motorPositonQueue01Handle, u_ctr_rx_msg.data, NULL, L980_CAN_MINI_TIME_MS);
        if(u_m_sta==osOK)
        {  //丢弃过期指令
          if(u_s_l980.sta.realPosition!=u_ctr_rx_msg.msg.targetPosition)
          {
            if(u_ctr_rx_msg.msg.targetPosition>L980_MAX_MOTOR_DISTANCE_UM||u_ctr_rx_msg.msg.moveCode==MOTOR_DIR_ZERO||u_ctr_rx_msg.msg.targetPosition==0)
            {//find zero
              u_ctr_rx_msg.msg.targetPosition=0;
              DEBUG_PRINTF("motor move to zero=%dμm zero\r\n",u_ctr_rx_msg.msg.targetPosition);
              app_motor_slide_position(MOTOR_DIR_ZERO,L980_MAX_MOTOR_DISTANCE_UM,3);
            }
            else
            {
              if(u_s_l980.sta.realPosition>u_ctr_rx_msg.msg.targetPosition)
              {
                DEBUG_PRINTF("motor move to=%dμm rever\r\n",u_ctr_rx_msg.msg.targetPosition);
                app_motor_slide_position(MOTOR_DIR_REVERSE,u_ctr_rx_msg.msg.targetPosition,3);
              }
              else {
                DEBUG_PRINTF("motor move to=%dμm forwar\r\n",u_ctr_rx_msg.msg.targetPosition);
                app_motor_slide_position(MOTOR_DIR_FORWARD,u_ctr_rx_msg.msg.targetPosition,3);
              }
            }
          }
        }
        m_timeOut = 0;
      }
      else
      {
        osDelay(L980_CAN_MINI_TIME_MS);
        m_timeOut+=L980_CAN_MINI_TIME_MS;
        if(m_timeOut>L980_MOTOR_MOVE_WAIT_TIMEOUT)
        {
          app_motor_err_handle(osErrorTimeout);
          break;
        }
      }
    }
    else
    {
      if((motor_events&EVENTS_MOTOR_IDLE_BIT1)==EVENTS_MOTOR_IDLE_BIT1)
      {
        GPIO_PinState zero_pin = HAL_GPIO_ReadPin(MOTOR_ZERO_CHECK_EXTI9_5_IN_GPIO_Port,MOTOR_ZERO_CHECK_EXTI9_5_IN_Pin);
        if(zero_pin==GPIO_PIN_RESET)
        {
          DEBUG_PRINTF(" reverse zero\r\n");
          u_ctr_rx_msg.msg.targetPosition=0;
          __HAL_TIM_SET_COUNTER(&htim3,MOTOR_MAX_UM);
          app_motor_slide_position(MOTOR_DIR_ZERO,MOTOR_MAX_UM,3);
        }
        else
        {
          u_ctr_rx_msg.msg.targetPosition=5000;
          DEBUG_PRINTF("prepare find zero \r\n");
          __HAL_TIM_SET_COUNTER(&htim3,1);
          app_motor_slide_position(MOTOR_DIR_FORWARD,5000,3);
        }
        m_timeOut = 0;
      }
      else
      {
        if(osMessageQueueGet(motorPositonQueue01Handle, u_ctr_rx_msg.data, NULL, L980_CAN_MINI_TIME_MS)==osOK)
        {
          DEBUG_PRINTF("motor is moving\r\n");
        }
        else
        {
          osDelay(L980_CAN_MINI_TIME_MS);
          m_timeOut+=L980_CAN_MINI_TIME_MS;
          if(m_timeOut>MOTOR_MOVE_ERROR_TIMEOUT_S)
          {
            app_motor_err_handle(osErrorTimeout);
            break;
          }
        }
      }
    }
    osDelay(5);
  }
  /* USER CODE END motorTask02 */
}

void CANopenTask03(void *argument)
{
  /* USER CODE BEGIN CANopenTask03 */
  /* Infinite loop */
  uint8_t buff[8];
  uint32_t Identifier;
  uint16_t len;
  uint32_t l980_heart_timeout = 0;
  for(;;)
  {
    if(FDCAN1_Receive_Msg(buff, &Identifier,&len))
    {
      uint8_t packageType = Identifier&0x01;
      if((Identifier&0xFE)==CAN_RTU_SLAVE_ID)
      {
        CAN_receivePackageHandle(buff,packageType);
        if( (u_s_l980.sta.staByte&L980_STA_HEART_BIT0)!=L980_STA_HEART_BIT0)
        {
          DEBUG_PRINTF("CAN-connect!");
           u_s_l980.sta.staByte|=L980_STA_HEART_BIT0;
        }
        l980_heart_timeout=0;
        if(u_l980.set_param.auxLedBulbDutySet!=u_sys_param.sys_config_param.auxLedBulbDutySet)
        {
          u_sys_param.sys_config_param.auxLedBulbDutySet=u_l980.set_param.auxLedBulbDutySet;
          if(u_sys_param.sys_config_param.auxLedBulbDutySet==0)app_auxiliary_bulb_pwm(u_sys_param.sys_config_param.auxLedBulbDutySet,DISABLE);
          else app_auxiliary_bulb_pwm(u_sys_param.sys_config_param.auxLedBulbDutySet,ENABLE);
        }
      }
    }
    else
    {
      l980_heart_timeout+=2;
      if(l980_heart_timeout>L980_CAN_FRAME_TIMEOUT)
      {//l980 heart timeout
        l980_heart_timeout=0;
        if(u_s_l980.sta.reserveByte==0)
        {
          if( (u_s_l980.sta.staByte&L980_STA_HEART_BIT0)==L980_STA_HEART_BIT0)
          {
            u_s_l980.sta.staByte&=(~L980_STA_HEART_BIT0);
            DEBUG_PRINTF("CAN-disconnect!");
          }
          if((u_s_l980.sta.staByte&L980_STA_PROHOT_BIT1)==L980_STA_PROHOT_BIT1)
          {
            if(laser_ctr_param.pro_hot!=0)
            {
              DEBUG_PRINTF("exit prohot");
              osSemaphoreRelease(laserCloseBinarySem03Handle);
              laser_ctr_param.pro_hot=0;
            }
          }
          else
          {
            u_s_l980.sta.staByte&=(~L980_STATUS_BYTE_MASK);
          }
        }
        else
        {//工程模式
          u_s_l980.sta.staByte|=L980_STA_HEART_BIT0;
        }
      }
    }
    osDelay(2);
  }
  /* USER CODE END CANopenTask03 */
}

void laserWorkTask04(void *argument)
{
  /* USER CODE BEGIN laserWorkTask04 */
  /* Infinite loop */
  unsigned int timeout ;
  U_MOTOR_CTR_MESSAGE u_ctr_tx_msg;
  for(;;)
  {
    uint32_t laser_event = osEventFlagsGet(laserEvent02Handle);
    osStatus_t c_sta= osSemaphoreAcquire(laserCloseBinarySem03Handle,5);
    if(c_sta==osOK&&(u_s_l980.sta.staByte&L980_STA_PROHOT_BIT1)==L980_STA_PROHOT_BIT1)
    {
      app_980_pwr_en(DISABLE);
      app_dac_out(0);
      u_s_l980.sta.staByte&=(~L980_STA_PULSEOUT_BIT2);
      osEventFlagsClear(laserEvent02Handle, EVENTS_LASER_VOLTAGE_BIT2);
      //position 0
      u_ctr_tx_msg.msg.moveCode=MOTOR_DIR_ZERO;
      u_ctr_tx_msg.msg.targetPosition=0;
      osStatus m_msg_sta= osMessageQueuePut(motorPositonQueue01Handle, u_ctr_tx_msg.data, NULL, L980_CAN_MINI_TIME_MS);
      if(m_msg_sta!=osOK)
      {
        DEBUG_PRINTF("980 motor ctr msg send fail,resend!\r\n");
        osDelay(L980_CAN_MINI_TIME_MS);
        osMessageQueuePut(motorPositonQueue01Handle, u_ctr_tx_msg.data, NULL, 0);
      }
      else {
        DEBUG_PRINTF("980 motor reverse zero cmd\r\n");
      }
      timeout=0;
      do
      {
        osDelay(L980_CAN_MINI_TIME_MS);
        timeout+=L980_CAN_MINI_TIME_MS;
        if(timeout>L980_MOTOR_MOVE_WAIT_TIMEOUT)
        {
          u_s_l980.sta.staByte|=L980_ERR_MOTOR_BIT7;
          DEBUG_PRINTF("980 motor error! exit prohot fail\r\n");
          break;
        }
      }while(u_s_l980.sta.realPosition!=0);
      if(u_s_l980.sta.realPosition==0)
      {
        osEventFlagsClear(laserEvent02Handle, EVENTS_LASER_POSITON_BIT0);
        osTimerStop(laserWorkTimer01Handle);
        u_s_l980.sta.staByte&=(~L980_STATUS_BYTE_MASK);
        DEBUG_PRINTF("l980 exit prohot ok\r\n");
      }
      else
      {
        DEBUG_PRINTF("l980 exit prohot fail!\r\n");
      }
    }
    if(laser_ctr_param.JT_laser_out!=0&&((u_s_l980.sta.staByte&L980_STA_PROHOT_BIT1)==L980_STA_PROHOT_BIT1))
    {
      if(u_l980.set_param.timerSet<=0&&(u_s_l980.sta.staByte&L980_STA_TIMERS_BIT3)==L980_STA_TIMERS_BIT3)
      {
        u_s_l980.sta.staByte&=(~L980_STA_TIMERS_BIT3);
        osTimerStop(laserWorkTimer01Handle);
      }
      if((u_s_l980.sta.staByte&L980_STA_PULSEOUT_BIT2)!=L980_STA_PULSEOUT_BIT2)
      {
        if(u_l980.set_param.timerSet>0)
        {
          u_s_l980.sta.staByte|=L980_STA_TIMERS_BIT3;
          osTimerStart(laserWorkTimer01Handle,abs(u_l980.set_param.timerSet));
        }
        app_980_pwr_en(ENABLE);
        u_s_l980.sta.staByte|=L980_STA_PULSEOUT_BIT2;
        DEBUG_PRINTF("l980 JT pulse out \r\n");
      }
    }
    else
    {
      osTimerStop(laserWorkTimer01Handle);
      u_s_l980.sta.staByte&=(~L980_STA_TIMERS_BIT3);
      if((u_s_l980.sta.staByte&L980_STA_PULSEOUT_BIT2)==L980_STA_PULSEOUT_BIT2)
      {
        DEBUG_PRINTF("l980 JT stop pulse out \r\n");
        app_980_pwr_en(DISABLE);
        u_s_l980.sta.staByte&=(~L980_STA_PULSEOUT_BIT2);
      }
    }
    osDelay(1);
  }
  /* USER CODE END laserWorkTask04 */
}

void laserProhotTask05(void *argument)
{
  /* USER CODE BEGIN laserProhotTask05 */
  /* Infinite loop */
  unsigned int timeout=0;
  unsigned char local_prohot;
  osStatus m_msg_sta;
  U_MOTOR_CTR_MESSAGE u_motor_ctr_msg;
  for(;;)
  {
    osSemaphoreAcquire(prohotBinarySem02Handle,portMAX_DELAY);
    local_prohot=laser_ctr_param.pro_hot;
    if(local_prohot!=0)
    {
      if((u_s_l980.sta.staByte&L980_STA_HEART_BIT0)!=L980_STA_HEART_BIT0)
      {
        DEBUG_PRINTF("l980 disconnect! exit prohot!\r\n");
        app_980_pwr_en(DISABLE);
        app_dac_out(0);
        u_s_l980.sta.dacValue=0;
        u_s_l980.sta.staByte&=(~L980_STA_PULSEOUT_BIT2);
        u_motor_ctr_msg.msg.moveCode=MOTOR_DIR_ZERO;
        u_motor_ctr_msg.msg.targetPosition=0;
        m_msg_sta= osMessageQueuePut(motorPositonQueue01Handle, u_motor_ctr_msg.data, NULL, L980_CAN_MINI_TIME_MS);
        if(m_msg_sta!=osOK)
        {
          DEBUG_PRINTF("980 motor ctr msg send fail,resend!\r\n");
          osDelay(L980_CAN_MINI_TIME_MS);
          osMessageQueuePut(motorPositonQueue01Handle, u_motor_ctr_msg.data, NULL, 0);
        }
        else {
          DEBUG_PRINTF("980 motor reverse zero cmd\r\n");
        }
        timeout=0;
        do
        {
          osDelay(L980_CAN_MINI_TIME_MS);
          timeout+=L980_CAN_MINI_TIME_MS;
          if(timeout>L980_MOTOR_MOVE_WAIT_TIMEOUT)
          {
            u_s_l980.sta.staByte|=L980_ERR_MOTOR_BIT7;
            DEBUG_PRINTF("980 motor error! exit prohot fail\r\n");
            break;
          }
        }while(u_s_l980.sta.realPosition!=0);
        if(u_s_l980.sta.realPosition==0)
        {
          u_s_l980.sta.staByte&=(~L980_ERR_MOTOR_BIT7);
          u_s_l980.sta.staByte&=(~L980_STA_PROHOT_BIT1);
          local_prohot=0;
          laser_ctr_param.pro_hot=0;
        }
      }
      else
      {
        if((u_s_l980.sta.staByte&L980_STA_PROHOT_BIT1)!=L980_STA_PROHOT_BIT1)
        {
          u_motor_ctr_msg.msg.moveCode=MOTOR_DIR_FORWARD;
          u_motor_ctr_msg.msg.targetPosition=u_l980.set_param.positionSet;
          m_msg_sta= osMessageQueuePut(motorPositonQueue01Handle, u_motor_ctr_msg.data, NULL, L980_CAN_MINI_TIME_MS);
          if(m_msg_sta!=osOK)
          {
            DEBUG_PRINTF("980 motor ctr msg send fail,resend!\r\n");
            osDelay(L980_CAN_MINI_TIME_MS);
            osMessageQueuePut(motorPositonQueue01Handle, u_motor_ctr_msg.data, NULL, 0);
          }
          else {
            DEBUG_PRINTF("motor move to %dum\r\n",u_motor_ctr_msg.msg.targetPosition);
          }
          //laser_ctr_param.energe=u_l980.set_param.energeSet+u_l980.set_param.energeCaliSet;
          //position
          timeout=0;
          do
          {
            osDelay(L980_CAN_MINI_TIME_MS);
            timeout+=L980_CAN_MINI_TIME_MS;
            if(timeout>L980_MOTOR_MOVE_WAIT_TIMEOUT)
            {
              u_s_l980.sta.staByte|=L980_ERR_MOTOR_BIT7;
              DEBUG_PRINTF("motor error %dum\r\n",u_s_l980.sta.realPosition);
              break;
            }
          }while(u_s_l980.sta.realPosition!=u_l980.set_param.positionSet);
          if(u_s_l980.sta.realPosition==u_l980.set_param.positionSet)
          {
            u_s_l980.sta.staByte&=(~L980_ERR_MOTOR_BIT7);
            osEventFlagsSet(laserEvent02Handle, EVENTS_LASER_POSITON_BIT0);
            //unsigned short int dac_voltage = app_laser_980_energe_to_voltage(u_s_l980.sta.useEnerge)+u_sys_param.sys_config_param.e_cali[u_s_l980.sta.useEnerge/5];
            //unsigned short int dac_voltage=app_laser_980_energe_to_voltage(u_s_l980.sta.useEnerge);//测试固定值
            app_dac_out(u_s_l980.sta.dacValue);
            osEventFlagsSet(laserEvent02Handle, EVENTS_LASER_VOLTAGE_BIT2);
          }
          else
          {
            u_s_l980.sta.staByte|=L980_ERR_MOTOR_BIT7;
            DEBUG_PRINTF("prohot motor error %dum\r\n",u_s_l980.sta.realPosition);
            osEventFlagsClear(laserEvent02Handle, EVENTS_LASER_POSITON_BIT0);
          }
          uint32_t laser_event=osEventFlagsGet(laserEvent02Handle);
          if((laser_event&EVENTS_LASER_OK_ALL_BITS_MASK)==EVENTS_LASER_OK_ALL_BITS_MASK)
          {
            u_s_l980.sta.staByte|=L980_STA_PROHOT_BIT1;
            DEBUG_PRINTF("l9890 prohot success\r\n");
          }
          else
          {
            u_s_l980.sta.staByte&=(~L980_STA_PROHOT_BIT1);
            app_dac_out(0);
            osEventFlagsClear(laserEvent02Handle, EVENTS_LASER_VOLTAGE_BIT2);
            u_s_l980.sta.staByte&=(~L980_STATUS_BYTE_MASK);
            DEBUG_PRINTF(" prohot fail\r\n");
          }
        }
      }
    }
    else
    {
      if((u_s_l980.sta.staByte&L980_STA_PROHOT_BIT1)==L980_STA_PROHOT_BIT1)  osSemaphoreRelease(laserCloseBinarySem03Handle);
    }
    osDelay(1);
  }
  /* USER CODE END laserProhotTask05 */
}

void powerOffTask06(void *argument)
{
  /* USER CODE BEGIN powerOffTask06 */
  /* Infinite loop */
  for(;;)
  {
    osStatus_t status = osSemaphoreAcquire(poweroffBinarySem04Handle,portMAX_DELAY);
    if((u_s_l980.sta.staByte&L980_STA_PROHOT_BIT1)==L980_STA_PROHOT_BIT1)
    {
      app_980_pwr_en(DISABLE);
      u_s_l980.sta.staByte&=(~L980_STA_PULSEOUT_BIT2);
      app_dac_out(0);
      u_s_l980.sta.dacValue=0;
      osSemaphoreRelease(laserCloseBinarySem03Handle);
      DEBUG_PRINTF(" exit hot\r\n");
    }
		if(app_sys_param_save_data()==0)
		{
			DEBUG_PRINTF(" sys param save ok\r\n");
		}
    HAL_Delay(200);
    #if 0
		while(1)
		{
			DEBUG_PRINTF("please release power key\r\n");//等待看门狗复位
			HAL_Delay(1000);
      #ifdef IWDG_USED
      HAL_IWDG_Refresh(&hiwdg1);
      #endif
		}
    #endif
   osDelay(1);

  }
  /* USER CODE END powerOffTask06 */
}

/* laserWorkTimerCallback01 function */
void laserWorkTimerCallback01(void *argument)
{
  /* USER CODE BEGIN laserWorkTimerCallback01 */
  if(u_l980.set_param.timerSet>0)
  {
    app_980_pwr_en(DISABLE);
    u_s_l980.sta.staByte&=(~(L980_STA_TIMERS_BIT3|L980_STA_PULSEOUT_BIT2));
  }
  /* USER CODE END laserWorkTimerCallback01 */
}

/* tecRunCallback02 function */
void tecRunCallback02(void *argument)
{
  /* USER CODE BEGIN tecRunCallback02 */
  tec_stop();
  /* USER CODE END tecRunCallback02 */
}

/* secondsHeartCallback03 function */
void secondsHeartCallback03(void *argument)
{
  /* USER CODE BEGIN secondsHeartCallback03 */
  if((u_s_l980.sta.staByte&L980_STA_PULSEOUT_BIT2)==L980_STA_PULSEOUT_BIT2)
  {
    u_sys_param.sys_config_param.laser_use_timeS++;
    u_s_l980.sta.laserUseTimeS=u_sys_param.sys_config_param.laser_use_timeS;
  }
  osSemaphoreRelease(secondHeartBinarySem04Handle);
  /* USER CODE END secondsHeartCallback03 */
}

/* USER CODE BEGIN Application */

void HAL_GPIO_EXTI_Callback(uint16_t GPIO_Pin)
{
  if(GPIO_Pin==MOTOR_ZERO_CHECK_EXTI9_5_IN_Pin)
  {
    DEBUG_PRINTF("HR zero \r\n");
  }
  if(GPIO_Pin==ECODER_Z_EXT2I_IN_Pin)
  {
    if(__HAL_TIM_IS_TIM_COUNTING_DOWN(&htim3))//down
    {
      if(HAL_GPIO_ReadPin(MOTOR_ZERO_CHECK_EXTI9_5_IN_GPIO_Port,MOTOR_ZERO_CHECK_EXTI9_5_IN_Pin)==GPIO_PIN_SET)
      {
        tmc2226_stop();
        u_s_l980.sta.staByte&=(~L980_ERR_MOTOR_BIT7);
        osEventFlagsSet(motorEvent01Handle,EVENTS_MOTOR_OK_ALL_BITS_MASK);
        DEBUG_PRINTF("index zero encode=%d \r\n",htim3.Instance->CNT);
        __HAL_TIM_SET_COUNTER(&htim3,0);
      }
    }
  }
}
/************************************************************************//**
  * @brief  relese
  * @param
  * @note
  * @retval None
  ****************************************************************************/
void app_tec_ctr_semo(void)
{
  osEventFlagsSet(tecEvent04Handle,EVENTS_TEC_STA_IDLE_BIT0);
}
/************************************************************************//**
  * @brief  relese
  * @param
  * @note
  * @retval None
  ****************************************************************************/
 void app_laser_prohot_semo(void)
 {
   osSemaphoreRelease(prohotBinarySem02Handle);
 }
   /************************************************************************//**
  * @brief laser
  * @param energe ,能量
  * @note   能量单位mJ;
  * @retval  换算后电压100mV
  *****************************************************************************/
 unsigned short int  app_laser_980_energe_to_voltage(unsigned short int energe)
 {
   unsigned short int ret_vol;
   ret_vol=energe*6+300;
   if(ret_vol<LASER_980_MIN_ENERGE_MV) ret_vol=LASER_980_MIN_ENERGE_MV;
   if(ret_vol>LASER_980_MAX_ENERGE_MV) ret_vol=LASER_980_MAX_ENERGE_MV;
   return ret_vol;
 }
 /************************************************************************//**
  * @brief  app_motor_run_sta
  * @param  runflag:0stop;1move
  * @note
  * @retval None
  ****************************************************************************/
 void app_motor_run_sta(unsigned char runFlag)
 {
  if(runFlag==0)  osEventFlagsSet(motorEvent01Handle,EVENTS_MOTOR_IDLE_BIT1);
  else  osEventFlagsClear(motorEvent01Handle,EVENTS_MOTOR_IDLE_BIT1);
 }
  /************************************************************************//**
  * @brief  app_motor_err_handle
  * @param  errSta
  * @note    只响应超时
  * @retval None
  ****************************************************************************/
 void app_motor_err_handle(osStatus_t errSta)
 {
    if(errSta!=osOK)
    {
      tmc2226_stop();
      u_s_l980.sta.staByte|=L980_ERR_MOTOR_BIT7;
      osEventFlagsSet(motorEvent01Handle,EVENTS_MOTOR_IDLE_BIT1);
      DEBUG_PRINTF("MOTOR error timeout !stop =%dμm\r\n",app_get_motor_real_position());
    }
 }
   /************************************************************************//**
  * @brief  电机正常停止并更新状态
  * @param  errSta
  * @note    只响应超时
  * @retval None
  ****************************************************************************/
 void app_motor_stop_fresh_status(void)
 {
    tmc2226_stop();
    u_s_l980.sta.staByte&=(~L980_ERR_MOTOR_BIT7);
    osEventFlagsSet(motorEvent01Handle,EVENTS_MOTOR_IDLE_BIT1);
    DEBUG_PRINTF("MOTOR stop =%dμm\r\n",app_get_motor_real_position());
 }
    /************************************************************************//**
  * @brief  app_motor_move_to_sem
  * @param  errSta
  * @note    电机移动
  * @retval None
  ****************************************************************************/
 void app_motor_move_to_sem(unsigned short int targetPosition)
 {
  osStatus msg_sta;
  U_MOTOR_CTR_MESSAGE u_ctr_msg;
  if(targetPosition==0)
  {
   // app_motor_stop_fresh_status();//立即停止
   DEBUG_PRINTF("motor stop !\r\n");
  }
  else if(targetPosition>=L980_MAX_MOTOR_DISTANCE_UM)
  {
    u_ctr_msg.msg.moveCode=MOTOR_DIR_ZERO;
    u_ctr_msg.msg.targetPosition=0;
    msg_sta= osMessageQueuePut(motorPositonQueue01Handle, u_ctr_msg.data, NULL, L980_CAN_MINI_TIME_MS);
    if(msg_sta!=osOK)
    {
      DEBUG_PRINTF("980 motor ctr msg send fail,resend!\r\n");
      osDelay(L980_CAN_MINI_TIME_MS);
      osMessageQueuePut(motorPositonQueue01Handle, u_ctr_msg.data, NULL, 0);
    }
    else {
      DEBUG_PRINTF("980 motor find zero\r\n");
    }
  }
  else
  {
    u_ctr_msg.msg.moveCode=MOTOR_DIR_FORWARD;
    u_ctr_msg.msg.targetPosition=targetPosition;
    msg_sta= osMessageQueuePut(motorPositonQueue01Handle, u_ctr_msg.data, NULL, L980_CAN_MINI_TIME_MS);
    if(msg_sta!=osOK)
    {
      DEBUG_PRINTF("980 motor ctr msg send fail,resend!\r\n");
      osDelay(L980_CAN_MINI_TIME_MS);
      osMessageQueuePut(motorPositonQueue01Handle, u_ctr_msg.data, NULL, 0);
    }
    else {
      DEBUG_PRINTF("980 motor move to =%dμm\r\n",targetPosition);
    }
  }
 }
/************************************************************************//**
* @brief  app_tec_auto_manage
* @param
* @note    1s handle
         volta,tec Voltage(max 24V)
* @retval None
****************************************************************************/
void app_tec_auto_manage(void)
{
  int volta;
  if(u_s_l980.sta.realtemprature>-400&&u_s_l980.sta.realtemprature>1500&&HAL_GPIO_ReadPin(TEC_DRV8701_ERROR_IN_GPIO_Port,TEC_DRV8701_ERROR_IN_Pin)==GPIO_PIN_SET)
  {//error
    osEventFlagsSet(tecEvent04Handle,EVENTS_TEC_ERR_BIT1);
  }
  else
  {
    osEventFlagsClear(tecEvent04Handle,EVENTS_TEC_ERR_BIT1);
  }
  uint32_t tec_evnet = osEventFlagsGet(tecEvent04Handle);
  if((tec_evnet&EVENTS_TEC_ERR_BIT1)==EVENTS_TEC_ERR_BIT1)
  {
    DEBUG_PRINTF("TEC error! check it\r\n");
    if(tec_evnet&EVENTS_TEC_STA_IDLE_BIT0) tec_stop();
  }
  else
  {
    if(tec_evnet&EVENTS_TEC_STA_IDLE_BIT0&&(u_s_l980.sta.staByte&L980_STA_PROHOT_BIT1)==L980_STA_PROHOT_BIT1&&u_s_l980.sta.tec_switch !=0)
    {
			if(u_s_l980.sta.realtemprature>u_sys_param.sys_config_param.targetTempratureSet+2)//>0.2
			{
				if(u_s_l980.sta.realtemprature>u_sys_param.sys_config_param.targetTempratureSet+15)//>1.5
				{
					volta = -40;
					osTimerStart(tecRunTimer02Handle,600);  //60%
				}
				else{
					volta = -20;
					osTimerStart(tecRunTimer02Handle,400);  //40%
				}
				osEventFlagsClear(tecEvent04Handle,EVENTS_TEC_STA_IDLE_BIT0);
				tec_start(volta,500);
			}
			else if(u_s_l980.sta.realtemprature+2<u_sys_param.sys_config_param.targetTempratureSet)//<-0.2
			{
				if(u_s_l980.sta.realtemprature+15<u_sys_param.sys_config_param.targetTempratureSet)//<1.5
				{
					volta = 40;
					osTimerStart(tecRunTimer02Handle,600);  //60%
				}
				else{
					volta = 20;
					osTimerStart(tecRunTimer02Handle,400);  //40%
				}
				osEventFlagsClear(tecEvent04Handle,EVENTS_TEC_STA_IDLE_BIT0);
				tec_start(volta,500);
			}
    }
  }
  if(u_s_l980.sta.realtemprature>300||u_s_l980.sta.realtemprature<160)
  {//温度超限
    u_s_l980.sta.staByte|=L980_ERR_TEMPRATURE_BIT4;
    osEventFlagsClear(laserEvent02Handle, EVENTS_LASER_TEMPRATUR_BIT1);
  }
  else
  {
    u_s_l980.sta.staByte&=(~L980_ERR_TEMPRATURE_BIT4);
    osEventFlagsSet(laserEvent02Handle, EVENTS_LASER_TEMPRATUR_BIT1);
  }
}
/************************************************************************//**
  * @brief 计算设备ID
  * @param 无
  * @note
  * @retval
  *****************************************************************************/
 unsigned  int app_get_cali_devid(void)
 {
   unsigned  int id;
   unsigned char buf[12];//96bit
   buf[0]=HAL_GetUIDw0()&0xFF;
   buf[1]=(HAL_GetUIDw0()>>8)&0xFF;
   buf[2]=(HAL_GetUIDw0()>>16)&0xFF;
   buf[3]=(HAL_GetUIDw0()>>24)&0xFF;

   buf[4]=HAL_GetUIDw1()&0xFF;
   buf[5]=(HAL_GetUIDw1()>>8)&0xFF;
   buf[6]=(HAL_GetUIDw1()>>16)&0xFF;
   buf[7]=(HAL_GetUIDw1()>>24)&0xFF;

   buf[8]=HAL_GetUIDw2()&0xFF;
   buf[9]=(HAL_GetUIDw2()>>8)&0xFF;
   buf[10]=(HAL_GetUIDw2()>>16)&0xFF;
   buf[11]=(HAL_GetUIDw2()>>24)&0xFF;
   id =  crc32_MPEG(buf,12);
   return id;
 }
 /************************************************************************//**
   * @brief 使用默认系统参数
   * @param 无
   * @note
   * @retval
   *****************************************************************************/
 void app_set_default_sys_config_param(void)
 {
    DEBUG_PRINTF("sys param load failed! load defalut param\r\n");
    u_sys_param.sys_config_param.deviceID= app_get_cali_devid();
    u_sys_param.sys_config_param.laser_use_timeS=0;
    u_sys_param.sys_config_param.targetTempratureSet=240;//23.0
    u_sys_param.sys_config_param.auxLedBulbDutySet=20;
    u_sys_param.sys_config_param.auxLedBulbFreqSet=10;//10k
    u_sys_param.sys_config_param.positionSet=33000;
    u_sys_param.sys_config_param.laTimerSet=180;
    for(unsigned short int i=0;i<41;i++)
    {
      u_sys_param.sys_config_param.e_cali[i]=800;
    }
    u_sys_param.sys_config_param.checkSum=sumCheck(u_sys_param.data,sizeof(SYS_CONFIG_PARAM)-4);
    memcpy(u_sys_default_param.data,u_sys_param.data,sizeof(SYS_CONFIG_PARAM));
    memcpy(u_l980.data,&u_sys_param.data[8],sizeof(L980_SET_PARAM));
    memset(u_s_l980.data,0,sizeof(L980_STATUS));
    u_s_l980.sta.laserUseTimeS=u_sys_param.sys_config_param.laser_use_timeS;
 }
 /************************************************************************//**
   * @brief 加载本地系统参数
   * @param 无
   * @note
   * @retval
   *****************************************************************************/
   void app_sys_param_load(void)
   {
     unsigned char flag;
     flag = EEPROM_M24C32_Read(EEROM_SYS_PARAM_SAVE_ADDR, u_sys_param.data, sizeof(SYS_CONFIG_PARAM));
     unsigned int sum = sumCheck(u_sys_param.data,sizeof(SYS_CONFIG_PARAM)-4);
     if(u_sys_param.sys_config_param.checkSum!=sum)//
     {
       app_set_default_sys_config_param();
       DEBUG_PRINTF("load default sys param\r\n");
     }
     else
     {
       memcpy(u_sys_default_param.data,u_sys_param.data,sizeof(SYS_CONFIG_PARAM));
       memcpy(u_l980.data,&u_sys_param.data[8],sizeof(L980_SET_PARAM));
       memset(u_s_l980.data,0,sizeof(L980_STATUS));
       u_s_l980.sta.laserUseTimeS=u_sys_param.sys_config_param.laser_use_timeS;

       #if 1
       DEBUG_PRINTF("***************sys param read ok*************************\r\n");

       DEBUG_PRINTF("*******************sys param end*************************\r\n");
       #endif
     }
   }
 /************************************************************************//**
   * @brief 系统参数保存到本地
   * @param 无
   * @note
   * @retval
   *****************************************************************************/
  unsigned char app_sys_param_save_data(void)
  {
     unsigned char flag=0;
     if(compare_buff_no_change(u_sys_param.data,u_sys_default_param.data,sizeof(SYS_CONFIG_PARAM))!=HAL_OK)
     {
       u_sys_param.sys_config_param.checkSum=sumCheck(u_sys_param.data,sizeof(SYS_CONFIG_PARAM)-4);
       flag = EEPROM_M24C32_Write(EEROM_SYS_PARAM_SAVE_ADDR, u_sys_param.data, sizeof(SYS_CONFIG_PARAM));
     }
     return flag;
  }
/************************************************************************//**
   * @brief 关机信号
   * @param 无
   * @note
   * @retval
   *****************************************************************************/
  void app_power_off_semo(void)
  {
    osSemaphoreRelease(poweroffBinarySem04Handle);
  }
/* USER CODE END Application */
